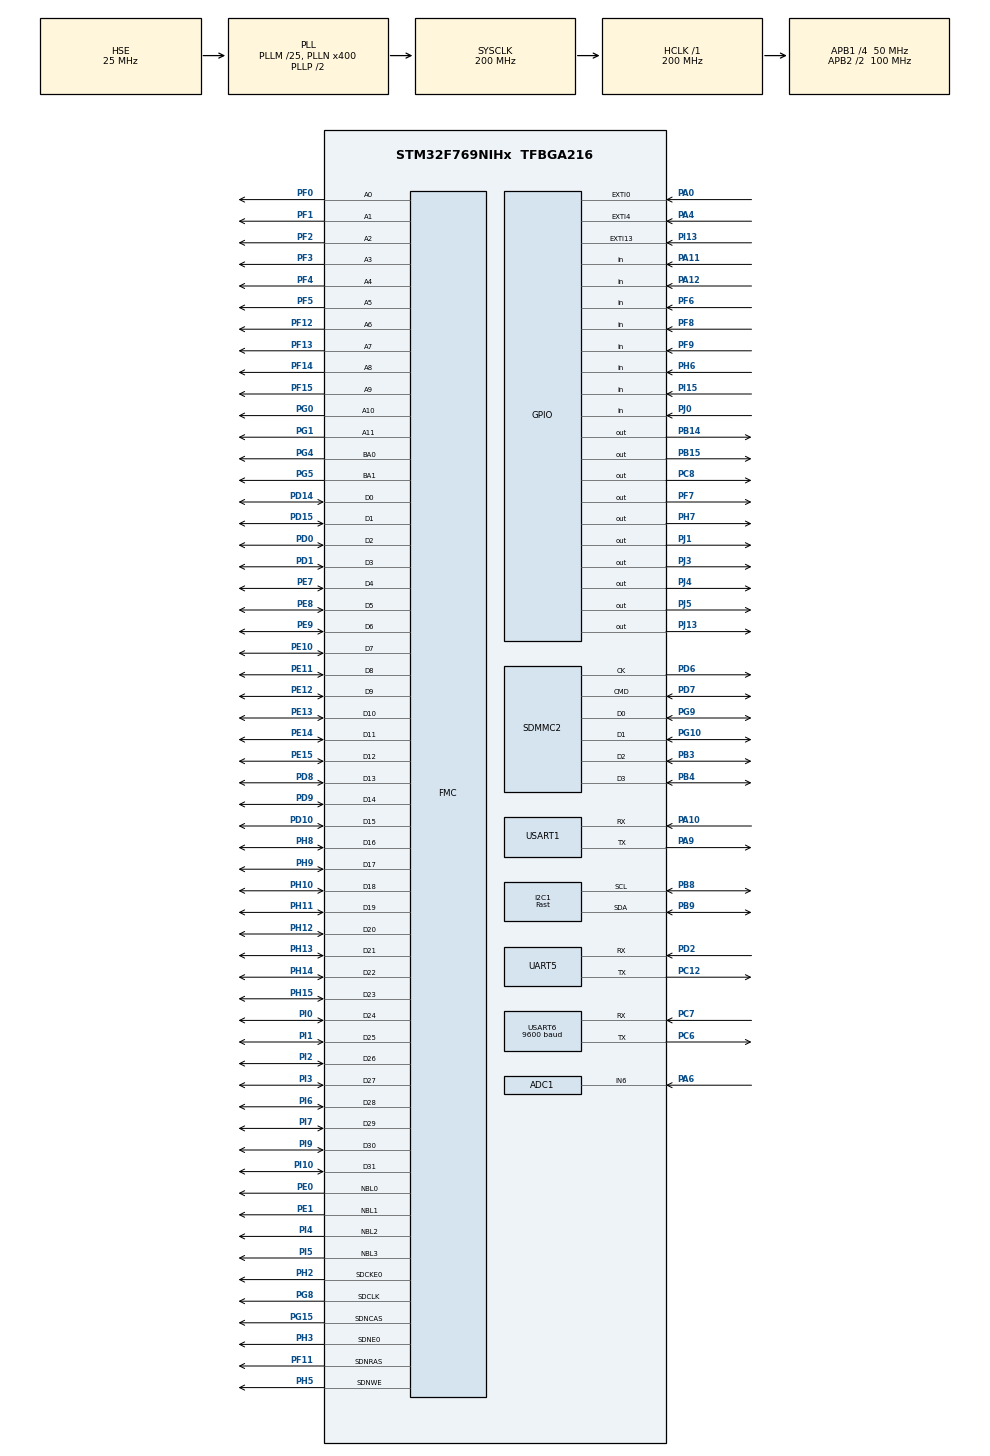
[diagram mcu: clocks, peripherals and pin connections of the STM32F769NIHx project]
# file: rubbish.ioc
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ADC1.Channel-0\#ChannelRegularConversion=ADC_CHANNEL_6
ADC1.ContinuousConvMode=ENABLE
ADC1.NbrOfConversionFlag=1
ADC1.Rank-0\#ChannelRegularConversion=1
ADC1.SamplingTime-0\#ChannelRegularConversion=ADC_SAMPLETIME_3CYCLES
ADC1.master=1
CORTEX_M7.ART_ACCLERATOR_ENABLE=1
CORTEX_M7.CPU_DCache=Enabled
CORTEX_M7.CPU_ICache=Enabled
CORTEX_M7.PREFETCH_ENABLE=1
DSIHOST.HorizontalBackPorch=273
DSIHOST.HorizontalLine=2643
DSIHOST.HorizontalSyncActive=273
DSIHOST.LPHorizontalBackPorchEnable=DSI_LP_HBP_ENABLE
DSIHOST.LPHorizontalFrontPorchEnable=DSI_LP_HFP_ENABLE
DSIHOST.LPVerticalActiveEnable=DSI_LP_VACT_ENABLE
DSIHOST.LPVerticalBackPorchEnable=DSI_LP_VBP_ENABLE
DSIHOST.LPVerticalFrontPorchEnable=DSI_LP_VFP_ENABLE
DSIHOST.LPVerticalSyncActiveEnable=DSI_LP_VSYNC_ENABLE
DSIHOST.Mode=DSI_VID_MODE_BURST
DSIHOST_CKN.Mode=DSIHost_Video
DSIHOST_CKN.Signal=DSIHOST_CKN
DSIHOST_CKP.Mode=DSIHost_Video
DSIHOST_CKP.Signal=DSIHOST_CKP
DSIHOST_D0N.Mode=DSIHost_Video
DSIHOST_D0N.Signal=DSIHOST_D0N
DSIHOST_D0P.Mode=DSIHost_Video
DSIHOST_D0P.Signal=DSIHOST_D0P
DSIHOST_D1N.Mode=DSIHost_Video
DSIHOST_D1N.Signal=DSIHOST_D1N
DSIHOST_D1P.Mode=DSIHost_Video
DSIHOST_D1P.Signal=DSIHOST_D1P
FATFS.BSP.number=1
FATFS._MAX_SS=4096
FATFS0.BSP.STBoard=false
FATFS0.BSP.api=Unknown
FATFS0.BSP.i2caddr=0
FATFS0.BSP.instance=PI15
FATFS0.BSP.ip=GPIO
FATFS0.BSP.mode=Input
FATFS0.BSP.name=Detect_SDIO
FATFS0.BSP.solution=PI15
FMC.CASLatency1=FMC_SDRAM_CAS_LATENCY_3
FMC.ExitSelfRefreshDelay1=7
FMC.LoadToActiveDelay1=2
FMC.RCDDelay1=2
FMC.RPDelay1=2
FMC.RPDelay2=2
FMC.ReadBurst1=FMC_SDRAM_RBURST_ENABLE
FMC.ReadBurst2=FMC_SDRAM_RBURST_ENABLE
FMC.RowCycleDelay1=7
FMC.RowCycleDelay2=7
FMC.SDClockPeriod1=FMC_SDRAM_CLOCK_PERIOD_2
FMC.SDClockPeriod2=FMC_SDRAM_CLOCK_PERIOD_2
FMC.SelfRefreshTime1=4
FMC.WriteRecoveryTime1=3
FREERTOS.Tasks01=defaultTask,0,1280,StartDefaultTask,Default,NULL,Dynamic,NULL,NULL
I2C1.I2C_Speed_Mode=I2C_Fast
I2C1.Timing=0x00401959
LTDC.ActiveW=800
LTDC.Alpha_L0=255
LTDC.BlendingFactor1_L0=LTDC_BLENDING_FACTOR1_PAxCA
LTDC.BlendingFactor2_L0=LTDC_BLENDING_FACTOR2_PAxCA
LTDC.HBP=120
LTDC.HFP=120
LTDC.HSPolarity=LTDC_HSPOLARITY_AH
LTDC.HSync=120
LTDC.ImageHeight_L0=480
LTDC.ImageWidth_L0=800
LTDC.Layers=0
LTDC.VBP=12
LTDC.VFP=12
LTDC.VSPolarity=LTDC_VSPOLARITY_AH
LTDC.VSync=12
LTDC.WindowX1_L0=800
LTDC.WindowY1_L0=480
Mcu.Family=STM32F7
Mcu.Name=STM32F769NIHx
Mcu.Package=TFBGA216
NVIC.EXTI0_IRQn=true\:5\:0\:false\:false\:true\:true\:true\:true
NVIC.EXTI15_10_IRQn=true\:5\:0\:false\:false\:true\:true\:true\:true
NVIC.EXTI4_IRQn=true\:5\:0\:false\:false\:true\:true\:true\:true
NVIC.PriorityGroup=NVIC_PRIORITYGROUP_4
NVIC.TIM1_UP_TIM10_IRQn=true\:0\:0\:false\:false\:true\:false\:false\:true
NVIC.TIM3_IRQn=true\:5\:0\:false\:false\:true\:true\:true\:true
NVIC.TimeBase=TIM1_UP_TIM10_IRQn
NVIC.TimeBaseIP=TIM1
NVIC.UART5_IRQn=true\:5\:0\:false\:false\:true\:true\:true\:true
NVIC.USART6_IRQn=true\:5\:0\:false\:false\:true\:true\:true\:true
PA0/WKUP.GPIO_ModeDefaultEXTI=GPIO_MODE_IT_RISING
PA0/WKUP.Signal=GPXTI0
PA10.Mode=Asynchronous
PA10.Signal=USART1_RX
PA11.GPIO_PuPd=GPIO_PULLDOWN
PA11.Signal=GPIO_Input
PA12.GPIO_PuPd=GPIO_PULLDOWN
PA12.Signal=GPIO_Input
PA13.Mode=Serial_Wire
PA13.Signal=SYS_JTMS-SWDIO
PA14.Mode=Serial_Wire
PA14.Signal=SYS_JTCK-SWCLK
PA4.GPIO_PuPd=GPIO_PULLDOWN
PA4.Signal=GPXTI4
PA6.Signal=ADCx_IN6
PA9.Mode=Asynchronous
PA9.Signal=USART1_TX
PB14.Signal=GPIO_Output
PB15.Signal=GPIO_Output
PB3.GPIO_PuPd=GPIO_PULLUP
PB3.Mode=SD_4_bits_Wide_bus
PB3.Signal=SDMMC2_D2
PB4.GPIO_PuPd=GPIO_PULLUP
PB4.Mode=SD_4_bits_Wide_bus
PB4.Signal=SDMMC2_D3
PB8.Mode=I2C
PB8.Signal=I2C1_SCL
PB9.Mode=I2C
PB9.Signal=I2C1_SDA
PC12.Mode=Asynchronous
PC12.Signal=UART5_TX
PC6.Mode=Asynchronous
PC6.Signal=USART6_TX
PC7.Mode=Asynchronous
PC7.Signal=USART6_RX
PC8.Signal=GPIO_Output
PD0.Signal=FMC_D2_DA2
PD1.Signal=FMC_D3_DA3
PD10.Signal=FMC_D15_DA15
PD14.Signal=FMC_D0_DA0
PD15.Signal=FMC_D1_DA1
PD2.Mode=Asynchronous
PD2.Signal=UART5_RX
PD6.GPIO_PuPd=GPIO_NOPULL
PD6.Mode=SD_4_bits_Wide_bus
PD6.Signal=SDMMC2_CK
PD7.GPIO_PuPd=GPIO_PULLUP
PD7.Mode=SD_4_bits_Wide_bus
PD7.Signal=SDMMC2_CMD
PD8.Signal=FMC_D13_DA13
PD9.Signal=FMC_D14_DA14
PE0.Signal=FMC_NBL0
PE1.Signal=FMC_NBL1
PE10.Signal=FMC_D7_DA7
PE11.Signal=FMC_D8_DA8
PE12.Signal=FMC_D9_DA9
PE13.Signal=FMC_D10_DA10
PE14.Signal=FMC_D11_DA11
PE15.Signal=FMC_D12_DA12
PE7.Signal=FMC_D4_DA4
PE8.Signal=FMC_D5_DA5
PE9.Signal=FMC_D6_DA6
PF0.Signal=FMC_A0
PF1.Signal=FMC_A1
PF11.Signal=FMC_SDNRAS
PF12.Signal=FMC_A6
PF13.Signal=FMC_A7
PF14.Signal=FMC_A8
PF15.Signal=FMC_A9
PF2.Signal=FMC_A2
PF3.Signal=FMC_A3
PF4.Signal=FMC_A4
PF5.Signal=FMC_A5
PF6.GPIO_PuPd=GPIO_PULLUP
PF6.Signal=GPIO_Input
PF7.GPIO_PuPd=GPIO_PULLUP
PF7.GPIO_Speed=GPIO_SPEED_FREQ_VERY_HIGH
PF7.PinState=GPIO_PIN_SET
PF7.Signal=GPIO_Output
PF8.GPIO_PuPd=GPIO_PULLDOWN
PF8.Signal=GPIO_Input
PF9.GPIO_PuPd=GPIO_PULLDOWN
PF9.Signal=GPIO_Input
PG0.Signal=FMC_A10
PG1.Signal=FMC_A11
PG10.GPIO_PuPd=GPIO_PULLUP
PG10.Mode=SD_4_bits_Wide_bus
PG10.Signal=SDMMC2_D1
PG15.Signal=FMC_SDNCAS
PG4.Signal=FMC_A14_BA0
PG5.Signal=FMC_A15_BA1
PG8.Signal=FMC_SDCLK
PG9.GPIO_PuPd=GPIO_PULLUP
PG9.Mode=SD_4_bits_Wide_bus
PG9.Signal=SDMMC2_D0
PH0/OSC_IN.Mode=HSE-External-Clock-Source
PH0/OSC_IN.Signal=RCC_OSC_IN
PH1/OSC_OUT.Mode=HSE-External-Clock-Source
PH1/OSC_OUT.Signal=RCC_OSC_OUT
PH10.Signal=FMC_D18
PH11.Signal=FMC_D19
PH12.Signal=FMC_D20
PH13.Signal=FMC_D21
PH14.Signal=FMC_D22
PH15.Signal=FMC_D23
PH2.Mode=SdramChipSelect1_1
PH2.Signal=FMC_SDCKE0
PH3.Mode=SdramChipSelect1_1
PH3.Signal=FMC_SDNE0
PH5.Signal=FMC_SDNWE
PH6.GPIO_PuPd=GPIO_PULLDOWN
PH6.Signal=GPIO_Input
PH7.Signal=GPIO_Output
PH8.Signal=FMC_D16
PH9.Signal=FMC_D17
PI0.Signal=FMC_D24
PI1.Signal=FMC_D25
PI10.Signal=FMC_D31
PI13.GPIO_ModeDefaultEXTI=GPIO_MODE_IT_FALLING
PI13.Signal=GPXTI13
PI15.GPIO_PuPd=GPIO_PULLUP
PI15.Signal=GPIO_Input
PI2.Signal=FMC_D26
PI3.Signal=FMC_D27
PI4.Signal=FMC_NBL2
PI5.Signal=FMC_NBL3
PI6.Signal=FMC_D28
PI7.Signal=FMC_D29
PI9.Signal=FMC_D30
PJ0.GPIO_PuPd=GPIO_PULLUP
PJ0.Signal=GPIO_Input
PJ1.Signal=GPIO_Output
PJ13.Signal=GPIO_Output
PJ3.GPIO_PuPd=GPIO_PULLUP
PJ3.GPIO_Speed=GPIO_SPEED_FREQ_VERY_HIGH
PJ3.PinState=GPIO_PIN_SET
PJ3.Signal=GPIO_Output
PJ4.Signal=GPIO_Output
PJ5.Signal=GPIO_Output
ProjectManager.HeapSize=0x2000
ProjectManager.StackSize=0x4000
ProjectManager.TargetToolchain=MDK-ARM V5
RCC.AHBFreq_Value=200000000
RCC.APB1CLKDivider=RCC_HCLK_DIV4
RCC.APB1Freq_Value=50000000
RCC.APB1TimFreq_Value=100000000
RCC.APB2CLKDivider=RCC_HCLK_DIV2
RCC.APB2Freq_Value=100000000
RCC.APB2TimFreq_Value=200000000
RCC.CortexFreq_Value=200000000
RCC.HCLKFreq_Value=200000000
RCC.HSE_VALUE=25000000
RCC.HSI_VALUE=16000000
RCC.LSE_VALUE=32768
RCC.PLLM=25
RCC.PLLN=400
RCC.PLLQ=8
RCC.PLLSourceVirtual=RCC_PLLSOURCE_HSE
RCC.SDMMC2ClockSelection=RCC_SDMMC2CLKSOURCE_CLK48
RCC.SYSCLKFreq_VALUE=200000000
RCC.SYSCLKSource=RCC_SYSCLKSOURCE_PLLCLK
RCC.USBFreq_Value=50000000
RCC.VCOOutputFreq_Value=400000000
SDMMC2.ClockDiv=0
SH.ADCx_IN6.0=ADC1_IN6,IN6
SH.FMC_A0.0=FMC_A0,12b-sda1
SH.FMC_A1.0=FMC_A1,12b-sda1
SH.FMC_A10.0=FMC_A10,12b-sda1
SH.FMC_A11.0=FMC_A11,12b-sda1
SH.FMC_A14_BA0.0=FMC_BA0,FourSdramBanks1
SH.FMC_A15_BA1.0=FMC_BA1,FourSdramBanks1
SH.FMC_A2.0=FMC_A2,12b-sda1
SH.FMC_A3.0=FMC_A3,12b-sda1
SH.FMC_A4.0=FMC_A4,12b-sda1
SH.FMC_A5.0=FMC_A5,12b-sda1
SH.FMC_A6.0=FMC_A6,12b-sda1
SH.FMC_A7.0=FMC_A7,12b-sda1
SH.FMC_A8.0=FMC_A8,12b-sda1
SH.FMC_A9.0=FMC_A9,12b-sda1
SH.FMC_D0_DA0.0=FMC_D0,sd-32b-d1
SH.FMC_D10_DA10.0=FMC_D10,sd-32b-d1
SH.FMC_D11_DA11.0=FMC_D11,sd-32b-d1
SH.FMC_D12_DA12.0=FMC_D12,sd-32b-d1
SH.FMC_D13_DA13.0=FMC_D13,sd-32b-d1
SH.FMC_D14_DA14.0=FMC_D14,sd-32b-d1
SH.FMC_D15_DA15.0=FMC_D15,sd-32b-d1
SH.FMC_D16.0=FMC_D16,sd-32b-d1
SH.FMC_D17.0=FMC_D17,sd-32b-d1
SH.FMC_D18.0=FMC_D18,sd-32b-d1
SH.FMC_D19.0=FMC_D19,sd-32b-d1
SH.FMC_D1_DA1.0=FMC_D1,sd-32b-d1
SH.FMC_D20.0=FMC_D20,sd-32b-d1
SH.FMC_D21.0=FMC_D21,sd-32b-d1
SH.FMC_D22.0=FMC_D22,sd-32b-d1
SH.FMC_D23.0=FMC_D23,sd-32b-d1
SH.FMC_D24.0=FMC_D24,sd-32b-d1
SH.FMC_D25.0=FMC_D25,sd-32b-d1
SH.FMC_D26.0=FMC_D26,sd-32b-d1
SH.FMC_D27.0=FMC_D27,sd-32b-d1
SH.FMC_D28.0=FMC_D28,sd-32b-d1
SH.FMC_D29.0=FMC_D29,sd-32b-d1
SH.FMC_D2_DA2.0=FMC_D2,sd-32b-d1
SH.FMC_D30.0=FMC_D30,sd-32b-d1
SH.FMC_D31.0=FMC_D31,sd-32b-d1
SH.FMC_D3_DA3.0=FMC_D3,sd-32b-d1
SH.FMC_D4_DA4.0=FMC_D4,sd-32b-d1
SH.FMC_D5_DA5.0=FMC_D5,sd-32b-d1
SH.FMC_D6_DA6.0=FMC_D6,sd-32b-d1
SH.FMC_D7_DA7.0=FMC_D7,sd-32b-d1
SH.FMC_D8_DA8.0=FMC_D8,sd-32b-d1
SH.FMC_D9_DA9.0=FMC_D9,sd-32b-d1
SH.FMC_NBL0.0=FMC_NBL0,Sd4ByteEnable1
SH.FMC_NBL1.0=FMC_NBL1,Sd4ByteEnable1
SH.FMC_NBL2.0=FMC_NBL2,Sd4ByteEnable1
SH.FMC_NBL3.0=FMC_NBL3,Sd4ByteEnable1
SH.FMC_SDCLK.0=FMC_SDCLK,12b-sda1
SH.FMC_SDNCAS.0=FMC_SDNCAS,12b-sda1
SH.FMC_SDNRAS.0=FMC_SDNRAS,12b-sda1
SH.FMC_SDNWE.0=FMC_SDNWE,12b-sda1
TIM3.Period=1110
TIM3.Prescaler=99
USART1.VirtualMode-Asynchronous=VM_ASYNC
USART6.BaudRate=9600
USART6.VirtualMode-Asynchronous=VM_ASYNC
VP_DMA2D_VS_DMA2D.Mode=DMA2D_Activate
VP_FATFS_VS_SDIO.Mode=SDIO
VP_FREERTOS_VS_CMSIS_V1.Mode=CMSIS_V1
VP_LTDC_DSIMode.Mode=RGB888
VP_SYS_VS_tim1.Mode=TIM1
VP_TIM3_VS_ClockSourceINT.Mode=Internal
board=custom

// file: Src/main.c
/* USER CODE BEGIN Header */
/**
  ******************************************************************************
  * @file           : main.c
  * @brief          : Main program body
  ******************************************************************************
  * @attention
  *
  * <h2><center>&copy; Copyright (c) 2020 STMicroelectronics.
  * All rights reserved.</center></h2>
  *
  * This software component is licensed by ST under Ultimate Liberty license
  * SLA0044, the "License"; You may not use this file except in compliance with
  * the License. You may obtain a copy of the License at:
  *                             www.st.com/SLA0044
  *
  ******************************************************************************
  */
/* USER CODE END Header */

#include "main.h"
#include "cmsis_os.h"
#include "fatfs.h"

/* USER CODE BEGIN Includes */
#include "stm32f769i_discovery_lcd.h"
#include "stm32f769i_discovery.h"
#include "stm32f769i_discovery_ts.h"
#include "string.h"
#include "gui.h"
#include "stdlib.h"
#include "stdio.h"
#include "ScanerCodes_GM66.h"
#include "mechanics.h"
#include "esp.h"

Screen CurrentScreen;

HR4988_DriverTypeDef XDriver;

xQueueHandle gui_msg_q;
xQueueHandle err_msg_q;
osMessageQId TOUCH_Queue;

uint8_t sect[4096];
uint32_t ts_status = TS_OK;
#define LCD_FRAME_BUFFER SDRAM_DEVICE_ADDR

uint8_t* dma2d_in1;
uint8_t* dma2d_in2;

struct Image images[20];
//0 - main
//1 - help icon
//2 - settings icon
//3 - call icon
//4 - back icon
/* USER CODE END Includes */

ADC_HandleTypeDef hadc1;

DMA2D_HandleTypeDef hdma2d;

DSI_HandleTypeDef hdsi;

I2C_HandleTypeDef hi2c1;

LTDC_HandleTypeDef hltdc;

SD_HandleTypeDef hsd2;

TIM_HandleTypeDef htim3;

UART_HandleTypeDef huart5;
UART_HandleTypeDef huart1;
UART_HandleTypeDef huart6;

SDRAM_HandleTypeDef hsdram1;

osThreadId defaultTaskHandle;
/* USER CODE BEGIN PV */
TaskHandle_t xScanTaskHandle = NULL;
osThreadId scanTaskHandle;
osThreadId blinkTaskHandle;
osThreadId pressingTaskHandle;
osThreadId drawTaskHandle;
osThreadId touchTaskHandle;
/* USER CODE END PV */

void SystemClock_Config(void);
static void MX_GPIO_Init(void);
static void MX_DMA2D_Init(void);
static void MX_DSIHOST_DSI_Init(void);
static void MX_FMC_Init(void);
static void MX_I2C1_Init(void);
static void MX_LTDC_Init(void);
static void MX_SDMMC2_SD_Init(void);
static void MX_ADC1_Init(void);
static void MX_USART1_UART_Init(void);
static void MX_USART6_UART_Init(void);
static void MX_TIM3_Init(void);
static void MX_UART5_Init(void);

/* USER CODE BEGIN PFP */
extern void StartBlinkTask(void const * argument);
extern void ScreensDrawer(void const * argument);
extern void StartTouchTask(void const * argument);
extern void StartPressingTask(void const * argument);
extern void StartScanTask(void const * argument);
/* USER CODE END PFP */

int main(void)
{
  /* USER CODE BEGIN 1 */
	//EXTI->IMR=(0<<EXTI_EMR_MR13_Pos)|(0<<EXTI_EMR_MR0_Pos);
  /* USER CODE END 1 */

  /* Enable I-Cache---------------------------------------------------------*/
  SCB_EnableICache();

  /* Enable D-Cache---------------------------------------------------------*/
  SCB_EnableDCache();

  /* MCU Configuration--------------------------------------------------------*/

  /* Reset of all peripherals, Initializes the Flash interface and the Systick. */
  HAL_Init();

  /* Configure the system clock */
  SystemClock_Config();

  /* Initialize all configured peripherals */
  MX_GPIO_Init();
  MX_DMA2D_Init();
  MX_DSIHOST_DSI_Init();
  MX_FMC_Init();
  MX_I2C1_Init();
  MX_LTDC_Init();
  MX_SDMMC2_SD_Init();
  MX_ADC1_Init();
  MX_FATFS_Init();
  MX_USART1_UART_Init();
  MX_USART6_UART_Init();
  MX_TIM3_Init();
  MX_UART5_Init();
  /* USER CODE BEGIN 2 */
	//MX_GPIO_Init_custom();
	HAL_GPIO_WritePin(SHIELD_ENABLE_PORT,SHIELD_ENABLE_PIN,GPIO_PIN_SET);
	strcpy(images[0].filename, "m_scr_v2.bmp");
	strcpy(images[1].filename, "help.h");//"bg_R.bmp"
	strcpy(images[2].filename, "settings.h");
	strcpy(images[3].filename, "call.h");
	strcpy(images[4].filename, "back.h");
	strcpy(images[5].filename, "0.h");
	strcpy(images[6].filename, "1.h");
	strcpy(images[7].filename, "2.h");
	strcpy(images[8].filename, "3.h");
	strcpy(images[9].filename, "4.h");
	strcpy(images[10].filename, "5.h");
	strcpy(images[11].filename, "6.h");
	strcpy(images[12].filename, "7.h");
	strcpy(images[13].filename, "8.h");
	strcpy(images[14].filename, "9.h");
	strcpy(images[15].filename, "perc.h");
	strcpy(images[16].filename, "cont_bot.h");
	strcpy(images[17].filename, "flp_grn.h");
	strcpy(images[18].filename, "flp_ylw.h");
	strcpy(images[19].filename, "flp_blue.h");

	strcpy(images[0].name, "main");
	strcpy(images[1].name, "i_help");
	strcpy(images[2].name, "i_settings");
	strcpy(images[3].name, "i_call");
	strcpy(images[4].name, "i_back");
	strcpy(images[5].name, "n_0");
	strcpy(images[6].name, "n_1");
	strcpy(images[7].name, "n_2");
	strcpy(images[8].name, "n_3");
	strcpy(images[9].name, "n_4");
	strcpy(images[10].name, "n_5");
	strcpy(images[11].name, "n_6");
	strcpy(images[12].name, "n_7");
	strcpy(images[13].name, "n_5");
	strcpy(images[14].name, "n_9");
	strcpy(images[15].name, "n_perc");
	strcpy(images[16].name, "i_cont");
	strcpy(images[17].name, "i_fgreen");
	strcpy(images[18].name, "i_fyellow");
	strcpy(images[19].name, "i_fblue");

//0xc011 frameb.stop
	images[0].location = (uint32_t *)0xC0300000;
	images[1].location = (uint32_t *)0xC0419800;//0xC0410800;
	images[2].location = (uint32_t *)0xC0439400;
	images[3].location = (uint32_t *)0xC0459000;
	images[4].location = (uint32_t *)0xC0478C00;
	images[5].location = (uint32_t *)0xC0498800; //0
	images[6].location = (uint32_t *)0xC049F400; //1
	images[7].location = (uint32_t *)0xC04ACC00; //2
	images[8].location = (uint32_t *)0xC04B3800; //3
	images[9].location = (uint32_t *)0xC04BA400; //4
	images[10].location = (uint32_t *)0xC04C1000; //5
	images[11].location = (uint32_t *)0xC04C7C00; //6
	images[12].location = (uint32_t *)0xC04CE800; //7
	images[13].location = (uint32_t *)0xC04D5400;
	images[14].location = (uint32_t *)0xC04DC000;
	images[15].location = (uint32_t *)0xC04E2C00;
	images[16].location = (uint32_t *)0xC04E4400; //container_bottom
	images[17].location = (uint32_t *)0xC060F864; //green flap
	images[18].location = (uint32_t *)0xC0643EE4; //yellow flap
	images[19].location = (uint32_t *)0xC0678564; //blue flap
																	//0xC1000000

	BSP_LCD_Init();
	BSP_LCD_LayerDefaultInit(0, LCD_FB_START_ADDRESS);
	//BSP_LCD_LayerDefaultInit(1, LCD_FB_START_ADDRESS_2);
	//BSP_LCD_SetLayerVisible(1, DISABLE);
	BSP_LCD_SetLayerVisible(0, ENABLE);
	BSP_LCD_SelectLayer(LTDC_ACTIVE_LAYER_BACKGROUND);
	TFT_FillScreen(LCD_COLOR_WHITE);
	InitBarcodeReader();
	espPower(ENABLE);

	//load images
	LoadImagesFromSdToRAM();

	//draw main screen
	Screen screenToLoad = MAIN;
	gui_msg_q = xQueueCreate(1, sizeof(Screen));
	xQueueSend(gui_msg_q, &screenToLoad, 0);

	//init touchscreen
	BSP_TS_Init(800,480);
	BSP_TS_ITConfig();
	osMessageQDef(touch_Queue, 1, uint8_t);
  TOUCH_Queue = osMessageCreate(osMessageQ(touch_Queue), NULL);

	uint8_t uart_str[20];
	sprintf((char*)uart_str,"Start\n");
	HAL_UART_Transmit(&huart1,uart_str,5,100);

	err_msg_q = xQueueCreate(1, sizeof(Error));
	rotationCounter(DISABLE);

	XDriver.DIR_Port=GPIOC;
	XDriver.DIR=GPIO_PIN_8;
	XDriver.STEP_Port=GPIOJ;
	XDriver.STEP=GPIO_PIN_1;
	XDriver.Timer=htim3;
	XDriver.PeriodStep=1;
	XDriver.StartCounterPeriod=0x456U; //450 Hz
	XDriver.StopCounterPeriod=0x1F3U;	 //1000 Hz
	XDriver.DriverDisable=0xFFU; //disable at every stop
	HR4988_DriverInit(&XDriver);
	HR4988_StopMotor(&XDriver);
  /* USER CODE END 2 */

  /* Create the thread(s) */
  /* definition and creation of defaultTask */

  /* USER CODE BEGIN RTOS_THREADS */
  /* add threads, ... */

	osThreadDef(scanTask, StartScanTask, osPriorityNormal, 0, 1024);
  scanTaskHandle = osThreadCreate(osThread(scanTask), &xScanTaskHandle);

	/* definition and creation of blinkTask */
  osThreadDef(blinkTask, StartBlinkTask, osPriorityNormal, 0, 32);
  blinkTaskHandle = osThreadCreate(osThread(blinkTask), NULL);

	/* definition and creation of drawTask */
  osThreadDef(drawTask, ScreensDrawer, osPriorityNormal, 0, 1024);
  drawTaskHandle = osThreadCreate(osThread(drawTask), NULL);

	/* definition and creation of touchTask */
  osThreadDef(touchTask, StartTouchTask, osPriorityBelowNormal, 0, 1024);
  touchTaskHandle = osThreadCreate(osThread(touchTask), NULL);

	/* definition and creation of pressingTask */
  osThreadDef(pressingTask, StartPressingTask, osPriorityHigh, 0, 512);
  touchTaskHandle = osThreadCreate(osThread(pressingTask), NULL);
  /* USER CODE END RTOS_THREADS */

  /* Start scheduler */
	HAL_GPIO_WritePin(SHIELD_ENABLE_PORT,SHIELD_ENABLE_PIN,GPIO_PIN_SET);
  osKernelStart();
  /* We should never get here as control is now taken by the scheduler */

  /* Infinite loop */
  while (1)
  {

  }
}

void SystemClock_Config(void)
{
  RCC_OscInitTypeDef RCC_OscInitStruct = {0};
  RCC_ClkInitTypeDef RCC_ClkInitStruct = {0};
  RCC_PeriphCLKInitTypeDef PeriphClkInitStruct = {0};

  /** Configure the main internal regulator output voltage
  */
  __HAL_RCC_PWR_CLK_ENABLE();
  __HAL_PWR_VOLTAGESCALING_CONFIG(PWR_REGULATOR_VOLTAGE_SCALE1);
  /** Initializes the CPU, AHB and APB busses clocks
  */
  RCC_OscInitStruct.OscillatorType = RCC_OSCILLATORTYPE_HSE;
  RCC_OscInitStruct.HSEState = RCC_HSE_BYPASS;
  RCC_OscInitStruct.PLL.PLLState = RCC_PLL_ON;
  RCC_OscInitStruct.PLL.PLLSource = RCC_PLLSOURCE_HSE;
  RCC_OscInitStruct.PLL.PLLM = 25;
  RCC_OscInitStruct.PLL.PLLN = 400;
  RCC_OscInitStruct.PLL.PLLP = RCC_PLLP_DIV2;
  RCC_OscInitStruct.PLL.PLLQ = 8;
  if (HAL_RCC_OscConfig(&RCC_OscInitStruct) != HAL_OK)
  {
    Error_Handler();
  }
  /** Activate the Over-Drive mode
  */
  if (HAL_PWREx_EnableOverDrive() != HAL_OK)
  {
    Error_Handler();
  }
  /** Initializes the CPU, AHB and APB busses clocks
  */
  RCC_ClkInitStruct.ClockType = RCC_CLOCKTYPE_HCLK|RCC_CLOCKTYPE_SYSCLK
                              |RCC_CLOCKTYPE_PCLK1|RCC_CLOCKTYPE_PCLK2;
  RCC_ClkInitStruct.SYSCLKSource = RCC_SYSCLKSOURCE_PLLCLK;
  RCC_ClkInitStruct.AHBCLKDivider = RCC_SYSCLK_DIV1;
  RCC_ClkInitStruct.APB1CLKDivider = RCC_HCLK_DIV4;
  RCC_ClkInitStruct.APB2CLKDivider = RCC_HCLK_DIV2;

  if (HAL_RCC_ClockConfig(&RCC_ClkInitStruct, FLASH_LATENCY_6) != HAL_OK)
  {
    Error_Handler();
  }
  PeriphClkInitStruct.PeriphClockSelection = RCC_PERIPHCLK_LTDC|RCC_PERIPHCLK_USART1
                              |RCC_PERIPHCLK_USART6|RCC_PERIPHCLK_UART5
                              |RCC_PERIPHCLK_I2C1|RCC_PERIPHCLK_SDMMC2
                              |RCC_PERIPHCLK_CLK48;
  PeriphClkInitStruct.PLLSAI.PLLSAIN = 192;
  PeriphClkInitStruct.PLLSAI.PLLSAIR = 2;
  PeriphClkInitStruct.PLLSAI.PLLSAIQ = 2;
  PeriphClkInitStruct.PLLSAI.PLLSAIP = RCC_PLLSAIP_DIV2;
  PeriphClkInitStruct.PLLSAIDivQ = 1;
  PeriphClkInitStruct.PLLSAIDivR = RCC_PLLSAIDIVR_2;
  PeriphClkInitStruct.Usart1ClockSelection = RCC_USART1CLKSOURCE_PCLK2;
  PeriphClkInitStruct.Uart5ClockSelection = RCC_UART5CLKSOURCE_PCLK1;
  PeriphClkInitStruct.Usart6ClockSelection = RCC_USART6CLKSOURCE_PCLK2;
  PeriphClkInitStruct.I2c1ClockSelection = RCC_I2C1CLKSOURCE_PCLK1;
  PeriphClkInitStruct.Clk48ClockSelection = RCC_CLK48SOURCE_PLL;
  PeriphClkInitStruct.Sdmmc2ClockSelection = RCC_SDMMC2CLKSOURCE_CLK48;
  if (HAL_RCCEx_PeriphCLKConfig(&PeriphClkInitStruct) != HAL_OK)
  {
    Error_Handler();
  }
}

static void MX_ADC1_Init(void)
{

  ADC_ChannelConfTypeDef sConfig = {0};

  /** Configure the global features of the ADC (Clock, Resolution, Data Alignment and number of conversion)
  */
  hadc1.Instance = ADC1;
  hadc1.Init.ClockPrescaler = ADC_CLOCK_SYNC_PCLK_DIV4;
  hadc1.Init.Resolution = ADC_RESOLUTION_12B;
  hadc1.Init.ScanConvMode = ADC_SCAN_DISABLE;
  hadc1.Init.ContinuousConvMode = ENABLE;
  hadc1.Init.DiscontinuousConvMode = DISABLE;
  hadc1.Init.ExternalTrigConvEdge = ADC_EXTERNALTRIGCONVEDGE_NONE;
  hadc1.Init.ExternalTrigConv = ADC_SOFTWARE_START;
  hadc1.Init.DataAlign = ADC_DATAALIGN_RIGHT;
  hadc1.Init.NbrOfConversion = 1;
  hadc1.Init.DMAContinuousRequests = DISABLE;
  hadc1.Init.EOCSelection = ADC_EOC_SINGLE_CONV;
  if (HAL_ADC_Init(&hadc1) != HAL_OK)
  {
    Error_Handler();
  }
  /** Configure for the selected ADC regular channel its corresponding rank in the sequencer and its sample time.
  */
  sConfig.Channel = ADC_CHANNEL_6;
  sConfig.Rank = ADC_REGULAR_RANK_1;
  sConfig.SamplingTime = ADC_SAMPLETIME_3CYCLES;
  if (HAL_ADC_ConfigChannel(&hadc1, &sConfig) != HAL_OK)
  {
    Error_Handler();
  }

}

static void MX_DMA2D_Init(void)
{

  hdma2d.Instance = DMA2D;
  hdma2d.Init.Mode = DMA2D_M2M;
  hdma2d.Init.ColorMode = DMA2D_OUTPUT_ARGB8888;
  hdma2d.Init.OutputOffset = 0;
  hdma2d.LayerCfg[1].InputOffset = 0;
  hdma2d.LayerCfg[1].InputColorMode = DMA2D_INPUT_ARGB8888;
  hdma2d.LayerCfg[1].AlphaMode = DMA2D_NO_MODIF_ALPHA;
  hdma2d.LayerCfg[1].InputAlpha = 0;
  hdma2d.LayerCfg[1].AlphaInverted = DMA2D_REGULAR_ALPHA;
  hdma2d.LayerCfg[1].RedBlueSwap = DMA2D_RB_REGULAR;
  if (HAL_DMA2D_Init(&hdma2d) != HAL_OK)
  {
    Error_Handler();
  }
  if (HAL_DMA2D_ConfigLayer(&hdma2d, 1) != HAL_OK)
  {
    Error_Handler();
  }

}

static void MX_DSIHOST_DSI_Init(void)
{

  DSI_PLLInitTypeDef PLLInit = {0};
  DSI_HOST_TimeoutTypeDef HostTimeouts = {0};
  DSI_PHY_TimerTypeDef PhyTimings = {0};
  DSI_VidCfgTypeDef VidCfg = {0};

  hdsi.Instance = DSI;
  hdsi.Init.AutomaticClockLaneControl = DSI_AUTO_CLK_LANE_CTRL_DISABLE;
  hdsi.Init.TXEscapeCkdiv = 4;
  hdsi.Init.NumberOfLanes = DSI_ONE_DATA_LANE;
  PLLInit.PLLNDIV = 20;
  PLLInit.PLLIDF = DSI_PLL_IN_DIV1;
  PLLInit.PLLODF = DSI_PLL_OUT_DIV1;
  if (HAL_DSI_Init(&hdsi, &PLLInit) != HAL_OK)
  {
    Error_Handler();
  }
  HostTimeouts.TimeoutCkdiv = 1;
  HostTimeouts.HighSpeedTransmissionTimeout = 0;
  HostTimeouts.LowPowerReceptionTimeout = 0;
  HostTimeouts.HighSpeedReadTimeout = 0;
  HostTimeouts.LowPowerReadTimeout = 0;
  HostTimeouts.HighSpeedWriteTimeout = 0;
  HostTimeouts.HighSpeedWritePrespMode = DSI_HS_PM_DISABLE;
  HostTimeouts.LowPowerWriteTimeout = 0;
  HostTimeouts.BTATimeout = 0;
  if (HAL_DSI_ConfigHostTimeouts(&hdsi, &HostTimeouts) != HAL_OK)
  {
    Error_Handler();
  }
  PhyTimings.ClockLaneHS2LPTime = 28;
  PhyTimings.ClockLaneLP2HSTime = 33;
  PhyTimings.DataLaneHS2LPTime = 15;
  PhyTimings.DataLaneLP2HSTime = 25;
  PhyTimings.DataLaneMaxReadTime = 0;
  PhyTimings.StopWaitTime = 0;
  if (HAL_DSI_ConfigPhyTimer(&hdsi, &PhyTimings) != HAL_OK)
  {
    Error_Handler();
  }
  if (HAL_DSI_ConfigFlowControl(&hdsi, DSI_FLOW_CONTROL_BTA) != HAL_OK)
  {
    Error_Handler();
  }
  if (HAL_DSI_SetLowPowerRXFilter(&hdsi, 10000) != HAL_OK)
  {
    Error_Handler();
  }
  if (HAL_DSI_ConfigErrorMonitor(&hdsi, HAL_DSI_ERROR_NONE) != HAL_OK)
  {
    Error_Handler();
  }
  VidCfg.VirtualChannelID = 0;
  VidCfg.ColorCoding = DSI_RGB888;
  VidCfg.LooselyPacked = DSI_LOOSELY_PACKED_DISABLE;
  VidCfg.Mode = DSI_VID_MODE_BURST;
  VidCfg.PacketSize = 800;
  VidCfg.NumberOfChunks = 0;
  VidCfg.NullPacketSize = 0;
  VidCfg.HSPolarity = DSI_HSYNC_ACTIVE_HIGH;
  VidCfg.VSPolarity = DSI_VSYNC_ACTIVE_HIGH;
  VidCfg.DEPolarity = DSI_DATA_ENABLE_ACTIVE_HIGH;
  VidCfg.HorizontalSyncActive = 273;
  VidCfg.HorizontalBackPorch = 273;
  VidCfg.HorizontalLine = 2643;
  VidCfg.VerticalSyncActive = 12;
  VidCfg.VerticalBackPorch = 12;
  VidCfg.VerticalFrontPorch = 12;
  VidCfg.VerticalActive = 480;
  VidCfg.LPCommandEnable = DSI_LP_COMMAND_DISABLE;
  VidCfg.LPLargestPacketSize = 0;
  VidCfg.LPVACTLargestPacketSize = 0;
  VidCfg.LPHorizontalFrontPorchEnable = DSI_LP_HFP_ENABLE;
  VidCfg.LPHorizontalBackPorchEnable = DSI_LP_HBP_ENABLE;
  VidCfg.LPVerticalActiveEnable = DSI_LP_VACT_ENABLE;
  VidCfg.LPVerticalFrontPorchEnable = DSI_LP_VFP_ENABLE;
  VidCfg.LPVerticalBackPorchEnable = DSI_LP_VBP_ENABLE;
  VidCfg.LPVerticalSyncActiveEnable = DSI_LP_VSYNC_ENABLE;
  VidCfg.FrameBTAAcknowledgeEnable = DSI_FBTAA_DISABLE;
  if (HAL_DSI_ConfigVideoMode(&hdsi, &VidCfg) != HAL_OK)
  {
    Error_Handler();
  }
  if (HAL_DSI_SetGenericVCID(&hdsi, 0) != HAL_OK)
  {
    Error_Handler();
  }

}

static void MX_I2C1_Init(void)
{

  hi2c1.Instance = I2C1;
  hi2c1.Init.Timing = 0x00401959;
  hi2c1.Init.OwnAddress1 = 0;
  hi2c1.Init.AddressingMode = I2C_ADDRESSINGMODE_7BIT;
  hi2c1.Init.DualAddressMode = I2C_DUALADDRESS_DISABLE;
  hi2c1.Init.OwnAddress2 = 0;
  hi2c1.Init.OwnAddress2Masks = I2C_OA2_NOMASK;
  hi2c1.Init.GeneralCallMode = I2C_GENERALCALL_DISABLE;
  hi2c1.Init.NoStretchMode = I2C_NOSTRETCH_DISABLE;
  if (HAL_I2C_Init(&hi2c1) != HAL_OK)
  {
    Error_Handler();
  }
  /** Configure Analogue filter
  */
  if (HAL_I2CEx_ConfigAnalogFilter(&hi2c1, I2C_ANALOGFILTER_ENABLE) != HAL_OK)
  {
    Error_Handler();
  }
  /** Configure Digital filter
  */
  if (HAL_I2CEx_ConfigDigitalFilter(&hi2c1, 0) != HAL_OK)
  {
    Error_Handler();
  }

}

static void MX_LTDC_Init(void)
{

  LTDC_LayerCfgTypeDef pLayerCfg = {0};

  hltdc.Instance = LTDC;
  hltdc.Init.HSPolarity = LTDC_HSPOLARITY_AH;
  hltdc.Init.VSPolarity = LTDC_VSPOLARITY_AH;
  hltdc.Init.DEPolarity = LTDC_DEPOLARITY_AL;
  hltdc.Init.PCPolarity = LTDC_PCPOLARITY_IPC;
  hltdc.Init.HorizontalSync = 119;
  hltdc.Init.VerticalSync = 11;
  hltdc.Init.AccumulatedHBP = 239;
  hltdc.Init.AccumulatedVBP = 23;
  hltdc.Init.AccumulatedActiveW = 1039;
  hltdc.Init.AccumulatedActiveH = 503;
  hltdc.Init.TotalWidth = 1159;
  hltdc.Init.TotalHeigh = 515;
  hltdc.Init.Backcolor.Blue = 0;
  hltdc.Init.Backcolor.Green = 0;
  hltdc.Init.Backcolor.Red = 0;
  if (HAL_LTDC_Init(&hltdc) != HAL_OK)
  {
    Error_Handler();
  }
  pLayerCfg.WindowX0 = 0;
  pLayerCfg.WindowX1 = 800;
  pLayerCfg.WindowY0 = 0;
  pLayerCfg.WindowY1 = 480;
  pLayerCfg.PixelFormat = LTDC_PIXEL_FORMAT_ARGB8888;
  pLayerCfg.Alpha = 255;
  pLayerCfg.Alpha0 = 0;
  pLayerCfg.BlendingFactor1 = LTDC_BLENDING_FACTOR1_PAxCA;
  pLayerCfg.BlendingFactor2 = LTDC_BLENDING_FACTOR2_PAxCA;
  pLayerCfg.FBStartAdress = 0;
  pLayerCfg.ImageWidth = 800;
  pLayerCfg.ImageHeight = 480;
  pLayerCfg.Backcolor.Blue = 0;
  pLayerCfg.Backcolor.Green = 0;
  pLayerCfg.Backcolor.Red = 0;
  if (HAL_LTDC_ConfigLayer(&hltdc, &pLayerCfg, 0) != HAL_OK)
  {
    Error_Handler();
  }

}

static void MX_SDMMC2_SD_Init(void)
{

  hsd2.Instance = SDMMC2;
  hsd2.Init.ClockEdge = SDMMC_CLOCK_EDGE_RISING;
  hsd2.Init.ClockBypass = SDMMC_CLOCK_BYPASS_DISABLE;
  hsd2.Init.ClockPowerSave = SDMMC_CLOCK_POWER_SAVE_DISABLE;
  hsd2.Init.BusWide = SDMMC_BUS_WIDE_1B;
  hsd2.Init.HardwareFlowControl = SDMMC_HARDWARE_FLOW_CONTROL_DISABLE;
  hsd2.Init.ClockDiv = 0;
  /* USER CODE BEGIN SDMMC2_Init 2 */
	HAL_SD_Init(&hsd2);
  /* USER CODE END SDMMC2_Init 2 */

}

static void MX_TIM3_Init(void)
{

  TIM_ClockConfigTypeDef sClockSourceConfig = {0};
  TIM_MasterConfigTypeDef sMasterConfig = {0};

  htim3.Instance = TIM3;
  htim3.Init.Prescaler = 99;
  htim3.Init.CounterMode = TIM_COUNTERMODE_UP;
  htim3.Init.Period = 1110;
  htim3.Init.ClockDivision = TIM_CLOCKDIVISION_DIV1;
  htim3.Init.AutoReloadPreload = TIM_AUTORELOAD_PRELOAD_DISABLE;
  if (HAL_TIM_Base_Init(&htim3) != HAL_OK)
  {
    Error_Handler();
  }
  sClockSourceConfig.ClockSource = TIM_CLOCKSOURCE_INTERNAL;
  if (HAL_TIM_ConfigClockSource(&htim3, &sClockSourceConfig) != HAL_OK)
  {
    Error_Handler();
  }
  sMasterConfig.MasterOutputTrigger = TIM_TRGO_RESET;
  sMasterConfig.MasterSlaveMode = TIM_MASTERSLAVEMODE_DISABLE;
  if (HAL_TIMEx_MasterConfigSynchronization(&htim3, &sMasterConfig) != HAL_OK)
  {
    Error_Handler();
  }

}

static void MX_UART5_Init(void)
{

  huart5.Instance = UART5;
  huart5.Init.BaudRate = 115200;
  huart5.Init.WordLength = UART_WORDLENGTH_8B;
  huart5.Init.StopBits = UART_STOPBITS_1;
  huart5.Init.Parity = UART_PARITY_NONE;
  huart5.Init.Mode = UART_MODE_TX_RX;
  huart5.Init.HwFlowCtl = UART_HWCONTROL_NONE;
  huart5.Init.OverSampling = UART_OVERSAMPLING_16;
  huart5.Init.OneBitSampling = UART_ONE_BIT_SAMPLE_DISABLE;
  huart5.AdvancedInit.AdvFeatureInit = UART_ADVFEATURE_NO_INIT;
  if (HAL_UART_Init(&huart5) != HAL_OK)
  {
    Error_Handler();
  }

}

static void MX_USART1_UART_Init(void)
{

  huart1.Instance = USART1;
  huart1.Init.BaudRate = 115200;
  huart1.Init.WordLength = UART_WORDLENGTH_8B;
  huart1.Init.StopBits = UART_STOPBITS_1;
  huart1.Init.Parity = UART_PARITY_NONE;
  huart1.Init.Mode = UART_MODE_TX_RX;
  huart1.Init.HwFlowCtl = UART_HWCONTROL_NONE;
  huart1.Init.OverSampling = UART_OVERSAMPLING_16;
  huart1.Init.OneBitSampling = UART_ONE_BIT_SAMPLE_DISABLE;
  huart1.AdvancedInit.AdvFeatureInit = UART_ADVFEATURE_NO_INIT;
  if (HAL_UART_Init(&huart1) != HAL_OK)
  {
    Error_Handler();
  }

}

static void MX_USART6_UART_Init(void)
{

  huart6.Instance = USART6;
  huart6.Init.BaudRate = 9600;
  huart6.Init.WordLength = UART_WORDLENGTH_8B;
  huart6.Init.StopBits = UART_STOPBITS_1;
  huart6.Init.Parity = UART_PARITY_NONE;
  huart6.Init.Mode = UART_MODE_TX_RX;
  huart6.Init.HwFlowCtl = UART_HWCONTROL_NONE;
  huart6.Init.OverSampling = UART_OVERSAMPLING_16;
  huart6.Init.OneBitSampling = UART_ONE_BIT_SAMPLE_DISABLE;
  huart6.AdvancedInit.AdvFeatureInit = UART_ADVFEATURE_NO_INIT;
  if (HAL_UART_Init(&huart6) != HAL_OK)
  {
    Error_Handler();
  }

}

/* FMC initialization function */
static void MX_FMC_Init(void)
{

  FMC_SDRAM_TimingTypeDef SdramTiming = {0};

  /** Perform the SDRAM1 memory initialization sequence
  */
  hsdram1.Instance = FMC_SDRAM_DEVICE;
  /* hsdram1.Init */
  hsdram1.Init.SDBank = FMC_SDRAM_BANK1;
  hsdram1.Init.ColumnBitsNumber = FMC_SDRAM_COLUMN_BITS_NUM_8;
  hsdram1.Init.RowBitsNumber = FMC_SDRAM_ROW_BITS_NUM_12;
  hsdram1.Init.MemoryDataWidth = FMC_SDRAM_MEM_BUS_WIDTH_32;
  hsdram1.Init.InternalBankNumber = FMC_SDRAM_INTERN_BANKS_NUM_4;
  hsdram1.Init.CASLatency = FMC_SDRAM_CAS_LATENCY_3;
  hsdram1.Init.WriteProtection = FMC_SDRAM_WRITE_PROTECTION_DISABLE;
  hsdram1.Init.SDClockPeriod = FMC_SDRAM_CLOCK_PERIOD_2;
  hsdram1.Init.ReadBurst = FMC_SDRAM_RBURST_ENABLE;
  hsdram1.Init.ReadPipeDelay = FMC_SDRAM_RPIPE_DELAY_0;
  /* SdramTiming */
  SdramTiming.LoadToActiveDelay = 2;
  SdramTiming.ExitSelfRefreshDelay = 7;
  SdramTiming.SelfRefreshTime = 4;
  SdramTiming.RowCycleDelay = 7;
  SdramTiming.WriteRecoveryTime = 3;
  SdramTiming.RPDelay = 2;
  SdramTiming.RCDDelay = 2;

  if (HAL_SDRAM_Init(&hsdram1, &SdramTiming) != HAL_OK)
  {
    Error_Handler( );
  }

}

static void MX_GPIO_Init(void)
{
  GPIO_InitTypeDef GPIO_InitStruct = {0};

  /* GPIO Ports Clock Enable */
  __HAL_RCC_GPIOE_CLK_ENABLE();
  __HAL_RCC_GPIOB_CLK_ENABLE();
  __HAL_RCC_GPIOD_CLK_ENABLE();
  __HAL_RCC_GPIOC_CLK_ENABLE();
  __HAL_RCC_GPIOA_CLK_ENABLE();
  __HAL_RCC_GPIOG_CLK_ENABLE();
  __HAL_RCC_GPIOJ_CLK_ENABLE();
  __HAL_RCC_GPIOI_CLK_ENABLE();
  __HAL_RCC_GPIOF_CLK_ENABLE();
  __HAL_RCC_GPIOH_CLK_ENABLE();

  /*Configure GPIO pin Output Level */
  HAL_GPIO_WritePin(GPIOJ, GPIO_PIN_13|GPIO_PIN_4|GPIO_PIN_5|GPIO_PIN_1, GPIO_PIN_RESET);

  /*Configure GPIO pin Output Level */
  HAL_GPIO_WritePin(GPIOC, GPIO_PIN_8, GPIO_PIN_RESET);

  /*Configure GPIO pin Output Level */
  HAL_GPIO_WritePin(GPIOF, GPIO_PIN_7, GPIO_PIN_SET);

  /*Configure GPIO pin Output Level */
  HAL_GPIO_WritePin(GPIOJ, GPIO_PIN_3, GPIO_PIN_SET);

  /*Configure GPIO pin Output Level */
  HAL_GPIO_WritePin(GPIOH, GPIO_PIN_7, GPIO_PIN_RESET);

  /*Configure GPIO pin Output Level */
  HAL_GPIO_WritePin(GPIOB, GPIO_PIN_14|GPIO_PIN_15, GPIO_PIN_RESET);

  /*Configure GPIO pins : PJ13 PJ4 PJ5 PJ1 */
  GPIO_InitStruct.Pin = GPIO_PIN_13|GPIO_PIN_4|GPIO_PIN_5|GPIO_PIN_1;
  GPIO_InitStruct.Mode = GPIO_MODE_OUTPUT_PP;
  GPIO_InitStruct.Pull = GPIO_NOPULL;
  GPIO_InitStruct.Speed = GPIO_SPEED_FREQ_LOW;
  HAL_GPIO_Init(GPIOJ, &GPIO_InitStruct);

  /*Configure GPIO pins : PA12 PA11 */
  GPIO_InitStruct.Pin = GPIO_PIN_12|GPIO_PIN_11;
  GPIO_InitStruct.Mode = GPIO_MODE_INPUT;
  GPIO_InitStruct.Pull = GPIO_PULLDOWN;
  HAL_GPIO_Init(GPIOA, &GPIO_InitStruct);

  /*Configure GPIO pin : PI13 */
  GPIO_InitStruct.Pin = GPIO_PIN_13;
  GPIO_InitStruct.Mode = GPIO_MODE_IT_FALLING;
  GPIO_InitStruct.Pull = GPIO_NOPULL;
  HAL_GPIO_Init(GPIOI, &GPIO_InitStruct);

  /*Configure GPIO pin : PI15 */
  GPIO_InitStruct.Pin = GPIO_PIN_15;
  GPIO_InitStruct.Mode = GPIO_MODE_INPUT;
  GPIO_InitStruct.Pull = GPIO_PULLUP;
  HAL_GPIO_Init(GPIOI, &GPIO_InitStruct);

  /*Configure GPIO pin : PC8 */
  GPIO_InitStruct.Pin = GPIO_PIN_8;
  GPIO_InitStruct.Mode = GPIO_MODE_OUTPUT_PP;
  GPIO_InitStruct.Pull = GPIO_NOPULL;
  GPIO_InitStruct.Speed = GPIO_SPEED_FREQ_LOW;
  HAL_GPIO_Init(GPIOC, &GPIO_InitStruct);

  /*Configure GPIO pin : PF7 */
  GPIO_InitStruct.Pin = GPIO_PIN_7;
  GPIO_InitStruct.Mode = GPIO_MODE_OUTPUT_PP;
  GPIO_InitStruct.Pull = GPIO_PULLUP;
  GPIO_InitStruct.Speed = GPIO_SPEED_FREQ_VERY_HIGH;
  HAL_GPIO_Init(GPIOF, &GPIO_InitStruct);

  /*Configure GPIO pins : PF6 PF9 PF8 */
  GPIO_InitStruct.Pin = GPIO_PIN_9|GPIO_PIN_8;
  GPIO_InitStruct.Mode = GPIO_MODE_INPUT;
  GPIO_InitStruct.Pull = GPIO_PULLDOWN;
  HAL_GPIO_Init(GPIOF, &GPIO_InitStruct);

  /*Configure GPIO pin : PA0 */
  GPIO_InitStruct.Pin = GPIO_PIN_0;
  GPIO_InitStruct.Mode = GPIO_MODE_IT_RISING;
  GPIO_InitStruct.Pull = GPIO_NOPULL;
  HAL_GPIO_Init(GPIOA, &GPIO_InitStruct);

	/*Configure GPIO pin : PF6 */
  GPIO_InitStruct.Pin = GPIO_PIN_6;
  GPIO_InitStruct.Mode = GPIO_MODE_OUTPUT_PP;
  GPIO_InitStruct.Pull = GPIO_PULLUP;
  HAL_GPIO_Init(GPIOF, &GPIO_InitStruct);

  /*Configure GPIO pin : PA4 */
  GPIO_InitStruct.Pin = GPIO_PIN_4;
  GPIO_InitStruct.Mode = GPIO_MODE_IT_RISING;
  GPIO_InitStruct.Pull = GPIO_PULLDOWN;
  HAL_GPIO_Init(GPIOA, &GPIO_InitStruct);

  /*Configure GPIO pin : PJ3 */
  GPIO_InitStruct.Pin = GPIO_PIN_3;
  GPIO_InitStruct.Mode = GPIO_MODE_OUTPUT_PP;
  GPIO_InitStruct.Pull = GPIO_PULLUP;
  GPIO_InitStruct.Speed = GPIO_SPEED_FREQ_VERY_HIGH;
  HAL_GPIO_Init(GPIOJ, &GPIO_InitStruct);

  /*Configure GPIO pin : PH7 */
  GPIO_InitStruct.Pin = GPIO_PIN_7;
  GPIO_InitStruct.Mode = GPIO_MODE_OUTPUT_PP;
  GPIO_InitStruct.Pull = GPIO_NOPULL;
  GPIO_InitStruct.Speed = GPIO_SPEED_FREQ_LOW;
  HAL_GPIO_Init(GPIOH, &GPIO_InitStruct);

  /*Configure GPIO pin : PH6 */
  GPIO_InitStruct.Pin = GPIO_PIN_6;
  GPIO_InitStruct.Mode = GPIO_MODE_INPUT;
  GPIO_InitStruct.Pull = GPIO_PULLDOWN;
  HAL_GPIO_Init(GPIOH, &GPIO_InitStruct);

  /*Configure GPIO pin : PJ0 */
  GPIO_InitStruct.Pin = GPIO_PIN_0;
  GPIO_InitStruct.Mode = GPIO_MODE_INPUT;
  GPIO_InitStruct.Pull = GPIO_PULLUP;
  HAL_GPIO_Init(GPIOJ, &GPIO_InitStruct);

  /*Configure GPIO pins : PB14 PB15 */
  GPIO_InitStruct.Pin = GPIO_PIN_14|GPIO_PIN_15;
  GPIO_InitStruct.Mode = GPIO_MODE_OUTPUT_PP;
  GPIO_InitStruct.Pull = GPIO_NOPULL;
  GPIO_InitStruct.Speed = GPIO_SPEED_FREQ_LOW;
  HAL_GPIO_Init(GPIOB, &GPIO_InitStruct);

  /* EXTI interrupt init*/
  HAL_NVIC_SetPriority(EXTI0_IRQn, 5, 0);
  HAL_NVIC_EnableIRQ(EXTI0_IRQn);

  HAL_NVIC_SetPriority(EXTI4_IRQn, 5, 0);
  HAL_NVIC_EnableIRQ(EXTI4_IRQn);

  HAL_NVIC_SetPriority(EXTI15_10_IRQn, 5, 0);
  HAL_NVIC_EnableIRQ(EXTI15_10_IRQn);

}

void HAL_TIM_PeriodElapsedCallback(TIM_HandleTypeDef *htim)
{
  if (htim->Instance == TIM1) {
    HAL_IncTick();
  }
  /* USER CODE BEGIN Callback 1 */
	HR4988_DriverCallback(htim);
  /* USER CODE END Callback 1 */
}

void Error_Handler(void)
{
  /* USER CODE BEGIN Error_Handler_Debug */
  /* User can add his own implementation to report the HAL error return state */
	HAL_GPIO_WritePin(GPIOJ,GPIO_PIN_13,GPIO_PIN_SET);
	while(1){}
  /* USER CODE END Error_Handler_Debug */
}

/************************ (C) COPYRIGHT STMicroelectronics *****END OF FILE****/

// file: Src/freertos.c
/* USER CODE BEGIN Header */
/**
  ******************************************************************************
  * File Name          : freertos.c
  * Description        : Code for freertos applications
  ******************************************************************************
  * @attention
  *
  * <h2><center>&copy; Copyright (c) 2020 STMicroelectronics.
  * All rights reserved.</center></h2>
  *
  * This software component is licensed by ST under Ultimate Liberty license
  * SLA0044, the "License"; You may not use this file except in compliance with
  * the License. You may obtain a copy of the License at:
  *                             www.st.com/SLA0044
  *
  ******************************************************************************
  */
/* USER CODE END Header */

#include "FreeRTOS.h"
#include "task.h"
#include "main.h"

/* USER CODE BEGIN Includes */
#include "cmsis_os.h"
#include "gui.h"
#include "stm32f769i_discovery_lcd.h"
#include "stdio.h"
#include "mechanics.h"
#include "ScanerCodes_GM66.h"
#include "esp.h"
/* USER CODE END Includes */

/* USER CODE BEGIN PD */

typedef enum {
    SCAN_CODE,

}Task;
/*
extern const uint16_t RightButtonX;
extern const uint16_t LeftButtonX;
extern const uint16_t TopButtonY;
extern const uint16_t BottomButtonY;
extern const uint16_t ContainerFlapsY;
extern const uint16_t ContainerYellowFlapX;
extern const uint16_t ContainerGreenFlapX;
extern const uint16_t ContainerBlueFlapX;
extern const uint16_t ContainerBottomX;
extern const uint16_t ContainerBottomY;
extern const uint16_t NumOnContainerY;
extern const uint8_t DistanceBetweenStrings48;*/

extern DMA2D_HandleTypeDef hdma2d;
extern LTDC_HandleTypeDef hltdc;
extern ADC_HandleTypeDef hadc1;
extern UART_HandleTypeDef huart6;
extern UART_HandleTypeDef huart1;
extern struct Image images[20];
extern Screen CurrentScreen;

TaskHandle_t xScanTaskH;
TaskHandle_t xPressingTaskH;
extern xQueueHandle gui_msg_q;
extern xQueueHandle err_msg_q;
extern osMessageQId TOUCH_Queue;

uint8_t Code[20] = {0};
uint8_t* test = Code;
uint8_t Command[20];
uint8_t Data_Recieve, Data_Analize, ScanCMD = 0;
uint32_t count = 0;
uint8_t rotation_counter = 0;
HAL_StatusTypeDef Status;

uint8_t DoorScreenState=0;
/* USER CODE END PD */

/* USER CODE BEGIN FunctionPrototypes */
void StartBlinkTask(void const * argument);
void ScreensDrawer(void const * argument);
void StartTouchTask(void const * argument);
void StartDefaultTask(void const * argument);
void StartPressingTask(void const * argument);
/* USER CODE END FunctionPrototypes */

/* GetIdleTaskMemory prototype (linked to static allocation support) */
void vApplicationGetIdleTaskMemory( StaticTask_t **ppxIdleTaskTCBBuffer, StackType_t **ppxIdleTaskStackBuffer, uint32_t *pulIdleTaskStackSize );

/* USER CODE BEGIN GET_IDLE_TASK_MEMORY */
static StaticTask_t xIdleTaskTCBBuffer;
static StackType_t xIdleStack[configMINIMAL_STACK_SIZE];

void vApplicationGetIdleTaskMemory( StaticTask_t **ppxIdleTaskTCBBuffer, StackType_t **ppxIdleTaskStackBuffer, uint32_t *pulIdleTaskStackSize )
{
  *ppxIdleTaskTCBBuffer = &xIdleTaskTCBBuffer;
  *ppxIdleTaskStackBuffer = &xIdleStack[0];
  *pulIdleTaskStackSize = configMINIMAL_STACK_SIZE;
  /* place for user code */
}
/* USER CODE END GET_IDLE_TASK_MEMORY */

/* USER CODE BEGIN Application */

void StartBlinkTask(void const * argument)
{	extern HR4988_DriverTypeDef XDriver;

	HR4988_RunMotor(&XDriver,CW_DIR);
  for(;;)
  {
		HAL_GPIO_TogglePin(GPIOJ,GPIO_PIN_5);
    osDelay(800);
  }
}

void StartPressingTask(void const * argument)
{
	xPressingTaskH=xTaskGetCurrentTaskHandle();
  for(;;)
  {
		ulTaskNotifyTake( pdTRUE, portMAX_DELAY );
		HAL_NVIC_DisableIRQ(EXTI0_IRQn);
		HAL_NVIC_DisableIRQ(EXTI15_10_IRQn);

		//there is no carriage
		if(HAL_GPIO_ReadPin(K_K1_PORT,K_K1_Pin)==0)driveCarriageToPos(START_POS);

		Error s = drivePress(DOWN);
		if(s == NO_ERR)
		{
			Screen screenl = MAIN;
			xQueueSend(gui_msg_q, &screenl, 0);
		}
		else if(s == OVERCURENT_PRESSING)
		{
			xQueueSend(err_msg_q, &s, 0);
			Screen screenl = ERR;
			xQueueSend(gui_msg_q, &screenl, 0);

			Error s = drivePress(UP);
			if(s != NO_ERR)
			{
				xQueueSend(err_msg_q, &s, 0);
				Screen screenl = ERR;
				xQueueSend(gui_msg_q, &screenl, 0);
			}
			doorBlock(0);
		}
		else
		{
			xQueueSend(err_msg_q, &s, 0);
			Screen screenl = ERR;
			xQueueSend(gui_msg_q, &screenl, 0);
		}
		HAL_NVIC_ClearPendingIRQ(EXTI0_IRQn);
		HAL_NVIC_ClearPendingIRQ(EXTI15_10_IRQn);
		HAL_NVIC_EnableIRQ(EXTI0_IRQn);
		HAL_NVIC_EnableIRQ(EXTI15_10_IRQn);
  }
}

void StartScanTask(void const * argument)
{
  /* USER CODE BEGIN 5 */
  /* Infinite loop */
	//uint8_t i=0, j=0, k=0;
	InitBarcodeReader();
	ScanCMD=0;
	uint8_t UartData[100] = {0};
	xScanTaskH=xTaskGetCurrentTaskHandle();
  for(;;)
  {
		ulTaskNotifyTake( pdTRUE, portMAX_DELAY );
		while(ScanCMD == 1)
		{
		if(ScanCMD != 0)
		{
			if(count >= 1000)
			{
				ReadCode(Command);
				Status = HAL_UART_Transmit(&huart6, Command, 9, 21);
				count = 0;
			}
			HAL_UART_Receive_IT(&huart6, &UartData[0], 100);
			if(count>=100)
			{
				//Analyze Data
				for(uint32_t i = 0; i < sizeof(UartData); i++ )
				{
					//Test Header
					if((UartData[i] == 0x02)&(UartData[i+1] == 0x0)&(UartData[i+2] == 0x0)&(UartData[i+3] == 0x01)&(UartData[i+4] == 0x0)&(UartData[i+5] == 0x33)&(UartData[i+6] == 0x31))
					{
						//Test Header
						i+=7;
						uint32_t j = 0;
						//Scan OK?
						while((j<13)&(UartData[i]>=0x30)&(UartData[i]<=0x39))
						{
							Code[j] = UartData[i];
							j++;
							i++;
						}
						//if scan is OK, complete scan
						if((j==13)&(UartData[i] == 0x0D))
						{
							ScanCMD =0;
							memset(UartData, 0, sizeof(UartData));
							//Code[13] = (uint8_t)"\0";
							uint8_t res = findCode((char*)Code);
							//processCode(Code);
							Screen screenToLoad;
							switch (res)
							{
								case 1: {
										//1 bin button
										DoorScreenState=1;
										screenToLoad = DOOR_OPEN;
										xQueueSend(gui_msg_q, &screenToLoad, 0);break;}
								case 2: {
										//1 bin button
										DoorScreenState=2;
										screenToLoad = DOOR_OPEN;
										xQueueSend(gui_msg_q, &screenToLoad, 0);break;}
								case 3: {
										//1 bin button
										DoorScreenState=3;
										screenToLoad = DOOR_OPEN;
										xQueueSend(gui_msg_q, &screenToLoad, 0);break;}
							}
						}
					}
				}
			}
			count++;
		}
		osDelay(1);
	}
		//HAL_GPIO_ReadPin(GPIOA,GPIO_PIN_0)
		/*
		if(CurrentScreen == 26)
		{
			//Touchscreen_Handle_NewTouch();
			//LCD_DrawBitmap(0,0,(uint8_t *)screens[0].location);
			DMA2D_DrawImage((uint32_t)images[16].location, 126, 70, 540, 400);
			osDelay(10);
			placePrBar(166,446,168,98,i,PROGRESSBAR_VERTICAL,0xFF00b800);
			placePrBar(350,446,168,98,j,PROGRESSBAR_VERTICAL,LCD_COLOR_YELLOW);
			placePrBar(536,446,168,98,k,PROGRESSBAR_VERTICAL,LCD_COLOR_BLUE);
			osDelay(5);
			DrawPercents();
			osDelay(5);
			PrintFullness(1,i);
			osDelay(5);
			PrintFullness(2,j);
			osDelay(5);
			PrintFullness(3,k);
			i++;
			j+=4;
			k+=11;
			if(i>100)i=0;
			if(j>100)j=0;
			if(k>100)k=0;
			osDelay(200);
		}
    osDelay(80);
		}*/

		//osDelay(1000);
	}
}

float u;
void ScreensDrawer(void const * argument)
{
  /* Infinite loop */
  for(;;)
  {
		uint8_t msg = 15;
		if (xQueueReceive(gui_msg_q, &msg, 0) == pdTRUE)
		{
			HAL_NVIC_DisableIRQ(EXTI0_IRQn);
			HAL_NVIC_DisableIRQ(EXTI15_10_IRQn);
			if(msg==MAIN)
			{
				//main screen
				CurrentScreen = MAIN;
				LCD_DrawBitmap(0,0,(uint8_t *)images[0].location);
				TFT_DrawBitmapToMem(0,0,(uint8_t *)images[0].location,(uint8_t *)LCD_FB_START_ADDRESS);
				DMA2D_DrawImage((uint32_t)images[1].location, RightButtonX, BottomButtonY, images[1].width, images[1].height);
				DMA2D_DrawImage((uint32_t)images[2].location, LeftButtonX, BottomButtonY, images[2].width, images[2].height);
				//DMA2D_DrawImage((uint32_t)images[3].location, RightButtonX, TopButtonY, 120, 120);
				DMA2D_DrawImage((uint32_t)images[16].location, ContainerBottomX, ContainerBottomY, images[16].width, images[16].height);
				osDelay(10);

				DMA2D_DrawImage((uint32_t)images[17].location, ContainerGreenFlapX, ContainerFlapsY, images[17].width, images[17].height);
				osDelay(5);
				DMA2D_DrawImage((uint32_t)images[18].location, ContainerYellowFlapX, ContainerFlapsY, images[18].width, images[18].height);
				osDelay(5);
				DMA2D_DrawImage((uint32_t)images[19].location, ContainerBlueFlapX, ContainerFlapsY, images[19].width, images[19].height);
				osDelay(5);

				placePrBar(166,420,168,98,0,PROGRESSBAR_VERTICAL,LCD_COLOR_GREENCONTAINER);
				placePrBar(350,420,168,98,0,PROGRESSBAR_VERTICAL,LCD_COLOR_YELLOW);
				placePrBar(536,420,168,98,0,PROGRESSBAR_VERTICAL,LCD_COLOR_BLUE);

				osDelay(10);
				PrintFullness(1,10);
				osDelay(5);
				PrintFullness(2,20);
				osDelay(5);
				PrintFullness(3,30);
				osDelay(5);
				DrawPercents();

			BSP_LCD_SetTextColor(LCD_COLOR_BLACK);

			BSP_LCD_SetFont(&rus48);
			BSP_LCD_SetTextColor(LCD_COLOR_DARKGREEN);
			BSP_LCD_DisplayStringAt(130, 434, (uint8_t*)StringPlastic, LEFT_MODE,0);//15 first string

			BSP_LCD_DisplayStringAt(330, 434, (uint8_t*)StringGlass, LEFT_MODE,0);

			BSP_LCD_DisplayStringAt(503, 434, (uint8_t*)StringMetal, LEFT_MODE,0);

			DoorScreenState=0;
			}

			else if(msg==SETTINGS)
			{
				//settings screen
				CurrentScreen = SETTINGS;
				LCD_DrawBitmap(0,0,(uint8_t *)images[0].location);
				DMA2D_DrawImage((uint32_t)images[4].location, LeftButtonX, TopButtonY, 120, 120);

				uint8_t lcd_string[10] = "";
				BSP_LCD_SetTextColor(LCD_COLOR_DARKGREEN);
				BSP_LCD_SetFont(&rus48);
				BSP_LCD_DisplayStringAt(0, 10, (uint8_t*)StringSettings, CENTER_MODE, 0);

				sprintf((char*)lcd_string, "ABCDEFGHIJKLMNOP");
				BSP_LCD_DisplayStringAt(200, 100, lcd_string, RIGHT_MODE,0);
				sprintf((char*)lcd_string, "QRSTUVWXYZ[\\]^_`a");
				BSP_LCD_DisplayStringAt(200, 135, lcd_string, RIGHT_MODE,0);
				HAL_ADC_Start(&hadc1);
				HAL_ADC_PollForConversion(&hadc1,100);
				uint16_t res = HAL_ADC_GetValue(&hadc1);
				HAL_ADC_Stop(&hadc1);
				uint8_t uart_str[20];
				sprintf((char*)uart_str,"adc: %d\n", res);
				HAL_UART_Transmit(&huart1,uart_str,strlen((char*)uart_str),100);
				//BSP_LCD_DrawCircle(750,10,40);

			}

			else if(msg==CALL)
			{
				//call screen
				CurrentScreen = CALL;
				LCD_DrawBitmap(0,0,(uint8_t *)images[0].location);
				DMA2D_DrawImage((uint32_t)images[4].location, LeftButtonX, TopButtonY, 120, 120);

				BSP_LCD_SetTextColor(LCD_COLOR_DARKGREEN);
				BSP_LCD_SetFont(&rus48);
				BSP_LCD_DisplayStringAt(0, 10, (uint8_t*)StringHelp, CENTER_MODE, 0);
				osDelay(10);
			}
			else if(msg==HELP)
			{
				//help screen
				CurrentScreen = HELP;
				LCD_DrawBitmap(0,0,(uint8_t *)images[0].location);
				DMA2D_DrawImage((uint32_t)images[4].location, LeftButtonX, TopButtonY, 120, 120);

				BSP_LCD_SetTextColor(LCD_COLOR_DARKGREEN);
				BSP_LCD_SetFont(&rus48);
				BSP_LCD_DisplayStringAt(0, 10, (uint8_t*)StringHelp, CENTER_MODE, 0);
				osDelay(10);
			}
			else if(msg==DOOR_OPEN)
			{
				CurrentScreen = DOOR_OPEN;
				//help screen
				LCD_DrawBitmap(0,0,(uint8_t *)images[0].location);
				//DMA2D_DrawImage((uint32_t)images[4].location, LeftButtonX, TopButtonY, 120, 120);

				DMA2D_DrawImage((uint32_t)images[16].location, ContainerBottomX, ContainerBottomY, images[16].width, images[16].height);
				osDelay(10);

				BSP_LCD_SetTextColor(LCD_COLOR_DARKGREEN);
				BSP_LCD_SetFont(&rus48);

				BSP_LCD_DisplayStringAt(130, 434, (uint8_t*)StringPlastic, LEFT_MODE,0);//15 first string

				BSP_LCD_DisplayStringAt(330, 434, (uint8_t*)StringGlass, LEFT_MODE,0);

				BSP_LCD_DisplayStringAt(503, 434, (uint8_t*)StringMetal, LEFT_MODE,0);

				if(DoorScreenState==0)
				{
				//bin is not chosen(initial screen)
				BSP_LCD_SetTextColor(LCD_COLOR_RED);
				BSP_LCD_DisplayStringAt(20, 8, (uint8_t*)StringRemoveCap, CENTER_MODE,0);
				BSP_LCD_SetTextColor(LCD_COLOR_DARKGREEN);
				BSP_LCD_DisplayStringAt(20, 8+DistanceBetweenStrings48, (uint8_t*)StringScanBarcodeOr, CENTER_MODE,0);
				BSP_LCD_DisplayStringAt(20, 8+DistanceBetweenStrings48*2, (uint8_t*)StringChooseBinManually, CENTER_MODE,0);
				ScanCMD = 1;

				xTaskNotifyGive(xScanTaskH);
				}
				else if(DoorScreenState==1)
				{
				//after click on 1 bin
				DMA2D_DrawImage((uint32_t)images[4].location, LeftButtonX, TopButtonY, 120, 120);
				osDelay(10);
				ScanCMD = 0;
				DMA2D_DrawImage((uint32_t)images[17].location, ContainerGreenFlapX, ContainerFlapsY, images[17].width, images[17].height);
				BSP_LCD_DisplayStringAt(145, 8, (uint8_t*)StringPlaceRubbishIntoBin, LEFT_MODE,0);
				BSP_LCD_DisplayStringAt(145, 8+DistanceBetweenStrings48, (uint8_t*)StringOrChooseAnotherBin, LEFT_MODE,0);
				}
				else if(DoorScreenState==2)
				{
				DMA2D_DrawImage((uint32_t)images[4].location, LeftButtonX, TopButtonY, 120, 120);
				osDelay(10);
				ScanCMD = 0;
				DMA2D_DrawImage((uint32_t)images[18].location, ContainerYellowFlapX, ContainerFlapsY, images[18].width, images[18].height);
				BSP_LCD_DisplayStringAt(145, 8, (uint8_t*)StringPlaceRubbishIntoBin, LEFT_MODE,0);
				BSP_LCD_DisplayStringAt(145, 8+DistanceBetweenStrings48, (uint8_t*)StringOrChooseAnotherBin, LEFT_MODE,0);
				}
				else if(DoorScreenState==3)
				{
				DMA2D_DrawImage((uint32_t)images[4].location, LeftButtonX, TopButtonY, 120, 120);
				osDelay(10);
				ScanCMD = 0;
				DMA2D_DrawImage((uint32_t)images[19].location, ContainerBlueFlapX, ContainerFlapsY, images[19].width, images[19].height);
				BSP_LCD_DisplayStringAt(145, 8, (uint8_t*)StringPlaceRubbishIntoBin, LEFT_MODE,0);
				BSP_LCD_DisplayStringAt(145, 8+DistanceBetweenStrings48, (uint8_t*)StringOrChooseAnotherBin, LEFT_MODE,0);
				}

			}
			else if(msg==PRESSING)
			{
				CurrentScreen = PRESSING;
				LCD_DrawBitmap(0,0,(uint8_t *)images[0].location);
				//DMA2D_DrawImage((uint32_t)images[4].location, LeftButtonX, TopButtonY, 120, 120);
				BSP_LCD_SetTextColor(LCD_COLOR_DARKGREEN);
				BSP_LCD_SetFont(&rus48);
				BSP_LCD_DisplayStringAt(20, 60, (uint8_t*)StringRubbishIsPressing, LEFT_MODE,0);
				BSP_LCD_DisplayStringAt(20, 60+DistanceBetweenStrings48, (uint8_t*)StringWait, LEFT_MODE,0);
				xTaskNotifyGive(xPressingTaskH);
			}
			else if(msg==SERVICE)
			{
				//service screen
				CurrentScreen = SERVICE;
				LCD_DrawBitmap(0,0,(uint8_t *)images[0].location);
				DMA2D_DrawImage((uint32_t)images[4].location, LeftButtonX, TopButtonY, 120, 120);

				uint8_t str[30];
				BSP_LCD_SetTextColor(LCD_COLOR_BLACK);
				BSP_LCD_SetFont(&Font20);
				sprintf((char*)str,"K_K1: %d\n\r",HAL_GPIO_ReadPin(K_K1_PORT, K_K1_Pin));
				BSP_LCD_DisplayStringAt(10, 10, (uint8_t*)str, LEFT_MODE, 1);
				sprintf((char*)str,"K_K2: %d\n\r",HAL_GPIO_ReadPin(K_K2_PORT, K_K2_Pin));
				BSP_LCD_DisplayStringAt(10, 40, (uint8_t*)str, LEFT_MODE, 1);
				sprintf((char*)str,"K_K3: %d\n\r",HAL_GPIO_ReadPin(K_K3_PORT, K_K3_Pin));
				BSP_LCD_DisplayStringAt(10, 70, (uint8_t*)str, LEFT_MODE, 1);
				sprintf((char*)str,"K_K4: %d\n\r",HAL_GPIO_ReadPin(K_K4_PORT, K_K4_Pin));
				BSP_LCD_DisplayStringAt(10, 100, (uint8_t*)str, LEFT_MODE, 1);
				sprintf((char*)str,"K_UP: %d\n\r",HAL_GPIO_ReadPin(K_PUP_PORT, K_PUP_Pin));
				BSP_LCD_DisplayStringAt(10, 130, (uint8_t*)str, LEFT_MODE, 1);
				sprintf((char*)str,"K_DN: %d\n\r",HAL_GPIO_ReadPin(K_PDN_PORT, K_PDN_Pin));
				BSP_LCD_DisplayStringAt(10, 160, (uint8_t*)str, LEFT_MODE, 1);
				sprintf((char*)str,"K_DOOR: %d\n\r",HAL_GPIO_ReadPin(DOOR_PORT, DOOR_Pin));
				BSP_LCD_DisplayStringAt(10, 190, (uint8_t*)str, LEFT_MODE, 1);

				uint8_t shift = 235;
				uint16_t shift_r = 430;
				BSP_LCD_DisplayStringAt(240, 70, (uint8_t*)"PRESS", LEFT_MODE, 0);
				BSP_LCD_DisplayStringAt(240, 70 + shift, (uint8_t*)"CARRIAGE", LEFT_MODE, 0);
				BSP_LCD_DisplayStringAt(240+shift_r, 70 + shift, (uint8_t*)"STOPOR", LEFT_MODE, 0);

				BSP_LCD_SetTextColor(LCD_COLOR_GREEN);
				BSP_LCD_FillRect(700,10,70,60); //refresh

				BSP_LCD_FillRect(200,10,110,60);
				BSP_LCD_FillRect(340,40,110,60);
				BSP_LCD_FillRect(200,100,110,60);

				BSP_LCD_FillRect(200,10+shift,110,60);
				BSP_LCD_FillRect(340,40+shift,110,60);
				BSP_LCD_FillRect(200,100+shift,110,60);

				BSP_LCD_FillRect(200+shift_r,10+shift,110,60);
				BSP_LCD_FillRect(200+shift_r,100+shift,110,60);
				BSP_LCD_SetTextColor(LCD_COLOR_BLACK);
				BSP_LCD_SetFont(&Font20);
				BSP_LCD_DisplayStringAt(710, 10, (uint8_t*)"REFRESH", LEFT_MODE, 0);
				BSP_LCD_DisplayStringAt(250, 35, (uint8_t*)"UP", LEFT_MODE, 0);
				BSP_LCD_DisplayStringAt(250, 100, (uint8_t*)"DOWN", LEFT_MODE, 0);
				BSP_LCD_DisplayStringAt(340, 40, (uint8_t*)"STOP", LEFT_MODE, 0);

				BSP_LCD_DisplayStringAt(250, 35+shift, (uint8_t*)"LEFT", LEFT_MODE, 0);
				BSP_LCD_DisplayStringAt(250, 100+shift, (uint8_t*)"RIGHT", LEFT_MODE, 0);
				BSP_LCD_DisplayStringAt(340, 40+shift, (uint8_t*)"STOP", LEFT_MODE, 0);

				BSP_LCD_DisplayStringAt(250+shift_r, 35+shift, (uint8_t*)"UP", LEFT_MODE, 0);
				BSP_LCD_DisplayStringAt(250+shift_r, 100+shift, (uint8_t*)"DOWN", LEFT_MODE, 0);
				osDelay(10);
			}
			else if(msg==ERR)
			{
				//error screen
				CurrentScreen = ERR;
				LCD_DrawBitmap(0,0,(uint8_t *)images[0].location);
				DMA2D_DrawImage((uint32_t)images[4].location, LeftButtonX, TopButtonY, 120, 120);

				BSP_LCD_SetTextColor(LCD_COLOR_DARKGREEN);
				BSP_LCD_SetFont(&rus48);
				BSP_LCD_DisplayStringAt(0, 10, (uint8_t*)StringError, CENTER_MODE, 0);

				Error e;
				xQueueReceive(err_msg_q, &e, 0);

				switch(e)
				{
					case OVERCURENT_PRESSING:
					{
						BSP_LCD_DisplayStringAt(20, 155, (uint8_t*)StringPressOverload, LEFT_MODE,0);
						break;
					}
					case OVERTIME_PRESSING:
					{
						BSP_LCD_DisplayStringAt(20, 155, (uint8_t*)StringPressTimeout, LEFT_MODE,0);
						break;
					}
					case OVERTIME_AFTERPRESSING:
					{
						BSP_LCD_DisplayStringAt(20, 155, (uint8_t*)StringPressTimeout, LEFT_MODE,0);
						break;
					}
					case OVERTIME_PRESSUP:
					{
						BSP_LCD_DisplayStringAt(20, 155, (uint8_t*)StringPressUpTimeout, LEFT_MODE,0);
						break;
					}
				}

				osDelay(10);
			}
			HAL_NVIC_ClearPendingIRQ(EXTI0_IRQn);
			HAL_NVIC_ClearPendingIRQ(EXTI15_10_IRQn);
			HAL_NVIC_EnableIRQ(EXTI0_IRQn);
			HAL_NVIC_EnableIRQ(EXTI15_10_IRQn);
		}
    osDelay(100);
  }
}

void StartTouchTask(void const * argument)
{
  /* Infinite loop */
	osEvent event;
	uint8_t lcd_string[60] = "";
	Screen screenToLoad;
  for(;;)
  {
		event = osMessageGet(TOUCH_Queue, 100);
  	if (event.status == osEventMessage)
		{
			//HAL_GPIO_WritePin(GPIOJ,GPIO_PIN_13,GPIO_PIN_SET);
			HAL_NVIC_DisableIRQ(EXTI0_IRQn);
			HAL_NVIC_DisableIRQ(EXTI15_10_IRQn);
			uint16_t x = 10000, y = 10000;
			get_touch_pos(&x, &y);
			print_touch_pos(x, y);
			switch(CurrentScreen){
					case SETTINGS:
						//actions for SETTINGS SCREEN
						if(x > 0 && x < 115 && y > 0 && y < 115)
						{
							//left top button
							//sprintf((char*)lcd_string, "left top");
							//BSP_LCD_DisplayStringAt(0, BSP_LCD_GetYSize() - 45, lcd_string, LEFT_MODE, 1);
							screenToLoad = MAIN;
							xQueueSend(gui_msg_q, &screenToLoad, 0);
						}
						break;
					case MAIN:
						/*if(x > 700 && y < 115)
						{
							//right top button
							sprintf((char*)lcd_string, "right top");
							BSP_LCD_DisplayStringAt(0, BSP_LCD_GetYSize() - 45, lcd_string, LEFT_MODE, 1);
							screenToLoad = CALL;
							xQueueSend(gui_msg_q, &screenToLoad, 0);
						}*/
						if(x > 700 && y > 320 && x <= 800 && y <= 480)
						{
								//right bottom button
								if(DebugMessages == 1){BSP_LCD_SetFont(&Font12); BSP_LCD_DisplayStringAt(0, BSP_LCD_GetYSize() - 45, (uint8_t*)"right top", LEFT_MODE, 1);}
								//screenToLoad = HELP;
								screenToLoad = SERVICE;
								xQueueSend(gui_msg_q, &screenToLoad, 0);
						}
						else if(x < 115 && y > 320 && y <=480)
						{
								//left bottom button
								if(DebugMessages == 1){BSP_LCD_SetFont(&Font12); BSP_LCD_DisplayStringAt(0, BSP_LCD_GetYSize() - 45, (uint8_t*)"left bottom", LEFT_MODE, 1);}
								screenToLoad = SETTINGS;
								xQueueSend(gui_msg_q, &screenToLoad, 0);
						}
						break;

					case CALL:
						if(x > 0 && x < 115 && y > 0 && y < 115)
						{
							//left top button
							screenToLoad = MAIN;
							xQueueSend(gui_msg_q, &screenToLoad, 0);
						}
						break;

					case HELP:
						if(x > 0 && x < 115 && y > 0 && y < 115)
						{
							//left top button
							screenToLoad = MAIN;
							xQueueSend(gui_msg_q, &screenToLoad, 0);
						}
						break;
					case SERVICE:
						if(x > 0 && x < 115 && y > 0 && y < 115)
						{
							//left top button
							if(DebugMessages == 1){BSP_LCD_SetFont(&Font12); BSP_LCD_DisplayStringAt(0, BSP_LCD_GetYSize() - 45, (uint8_t*)"left top", LEFT_MODE, 1);}
							screenToLoad = MAIN;
							xQueueSend(gui_msg_q, &screenToLoad, 0);
						}
						else if(x > 700 && y < 115)
						{
							//right top button
							if(DebugMessages == 1){BSP_LCD_SetFont(&Font12); BSP_LCD_DisplayStringAt(0, BSP_LCD_GetYSize() - 45, (uint8_t*)"right top", LEFT_MODE, 1);}
							screenToLoad = SERVICE;
							xQueueSend(gui_msg_q, &screenToLoad, 0);
						}
						else HandleDebugTouch(x, y);
						break;
					case ERR:
						if(x > 0 && x < 115 && y > 0 && y < 115)
						{
							//left top button
							screenToLoad = MAIN;
							xQueueSend(gui_msg_q, &screenToLoad, 0);
						}
						break;
					case DOOR_OPEN:
						if(x > 0 && x < 115 && y > 0 && y < 115)
						{
							//left top button
							screenToLoad = MAIN;
							xQueueSend(gui_msg_q, &screenToLoad, 0);
						}
						else if(x > ContainerBottomX && x < 280 && y > ContainerBottomY && y < 480 && DoorScreenState!=1)
						{
							//1 bin button
							DoorScreenState=1;

							//vTaskSuspend(xScanTaskHandle);
							screenToLoad = DOOR_OPEN;
							xQueueSend(gui_msg_q, &screenToLoad, 0);

						}
						else if(x > 350 && x < 450 && y > ContainerBottomY && y < 480 && DoorScreenState!=2)
						{
							//2 bin button
							DoorScreenState=2;

							screenToLoad = DOOR_OPEN;
							xQueueSend(gui_msg_q, &screenToLoad, 0);

						}
						else if(x > 520 && x < 630 && y > ContainerBottomY && y < 480 && DoorScreenState!=3)
						{
							//3 bin button

							DoorScreenState=3;
							screenToLoad = DOOR_OPEN;
							xQueueSend(gui_msg_q, &screenToLoad, 0);

						}
						break;
						/*
					case PRESSING:
						if(x > 0 && x < 115 && y > 0 && y < 115)
						{
							screenToLoad = MAIN;
							xQueueSend(gui_msg_q, &screenToLoad, 0);
						}
						break;*/
					default:
						break;
				}
		HAL_NVIC_ClearPendingIRQ(EXTI0_IRQn);
		HAL_NVIC_ClearPendingIRQ(EXTI15_10_IRQn);
		HAL_NVIC_EnableIRQ(EXTI0_IRQn);
		HAL_NVIC_EnableIRQ(EXTI15_10_IRQn);
	}
  osDelay(40);
  }
}
/* USER CODE END Application */

/************************ (C) COPYRIGHT STMicroelectronics *****END OF FILE****/
